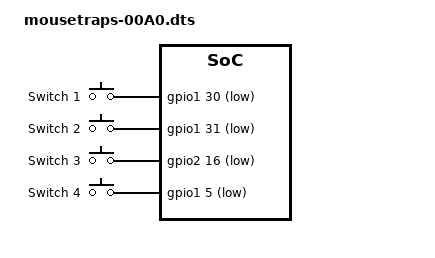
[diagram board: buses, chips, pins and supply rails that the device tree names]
/dts-v1/;
/plugin/;

/ {
	compatible = "ti,beaglebone-black";
	part-number = "mousetraps";
	version = "00A0";

	exclusive-use =
		"P9.11",
		"P9.13",
		"P9.15",
		"P9.17",
		"gpio0_30", "gpio0_31", "gpio1_16", "gpio0_05";

	/* https://github.com/derekmolloy/boneDeviceTree/blob/master/docs/BeagleboneBlackP9HeaderTable.pdf */
	/* http://hipstercircuits.com/capture-input-events-via-gpio-on-beaglebone-black/ */
	fragment@0 {
		target = <&am33xx_pinmux>;
		__overlay__ {
			mousetrap_pins: pinmux_mousetrap_pins {
				pinctrl-single,pins = <
					0x070 0x6f /* P9_11 30 slow INPUT MODE7 none */
					0x074 0x6f /* P9_13 31 slow INPUT MODE7 none */
					0x040 0x6f /* P9_15 48 slow INPUT MODE7 none */
					0x15c 0x6f /* P9_17 05 slow INPUT MODE7 none */
				>;
			};
		};	
	};

	fragment@1 {
		target = <&ocp>;
		__overlay__ {
			gpio_keys {
				compatible = "gpio-keys";
				pinctrl-names = "default";
				pinctrl-0 = <&mousetrap_pins>;

				switch_x1 {
					label = "Switch 1";
					debounce_interval = <50>;
					linux,code = <1>;
					gpios = <&gpio1 30 0x5>; /* gpio0+1, pin 30, input/pullup */
					gpio-key,wakeup;
				};              

				switch_x2 {
					label = "Switch 2";
					debounce_interval = <50>;
					linux,code = <1>;
					gpios = <&gpio1 31 0x5>; /* gpio0+1, pin 31, input/pullup */
					gpio-key,wakeup;
				};              

				switch_x3 {
					label = "Switch 3";
					debounce_interval = <50>;
					linux,code = <1>;
					gpios = <&gpio2 16 0x5>; /* gpio1+1, pin 2, input/pullup */
					gpio-key,wakeup;
				};              

				switch_x4 {
					label = "Switch 4";
					debounce_interval = <50>;
					linux,code = <1>;
					gpios = <&gpio1 5 0x5>; /* gpio0+1, pin 2, input/pullup */
					gpio-key,wakeup;
				};              
			};

		};
	};
};
